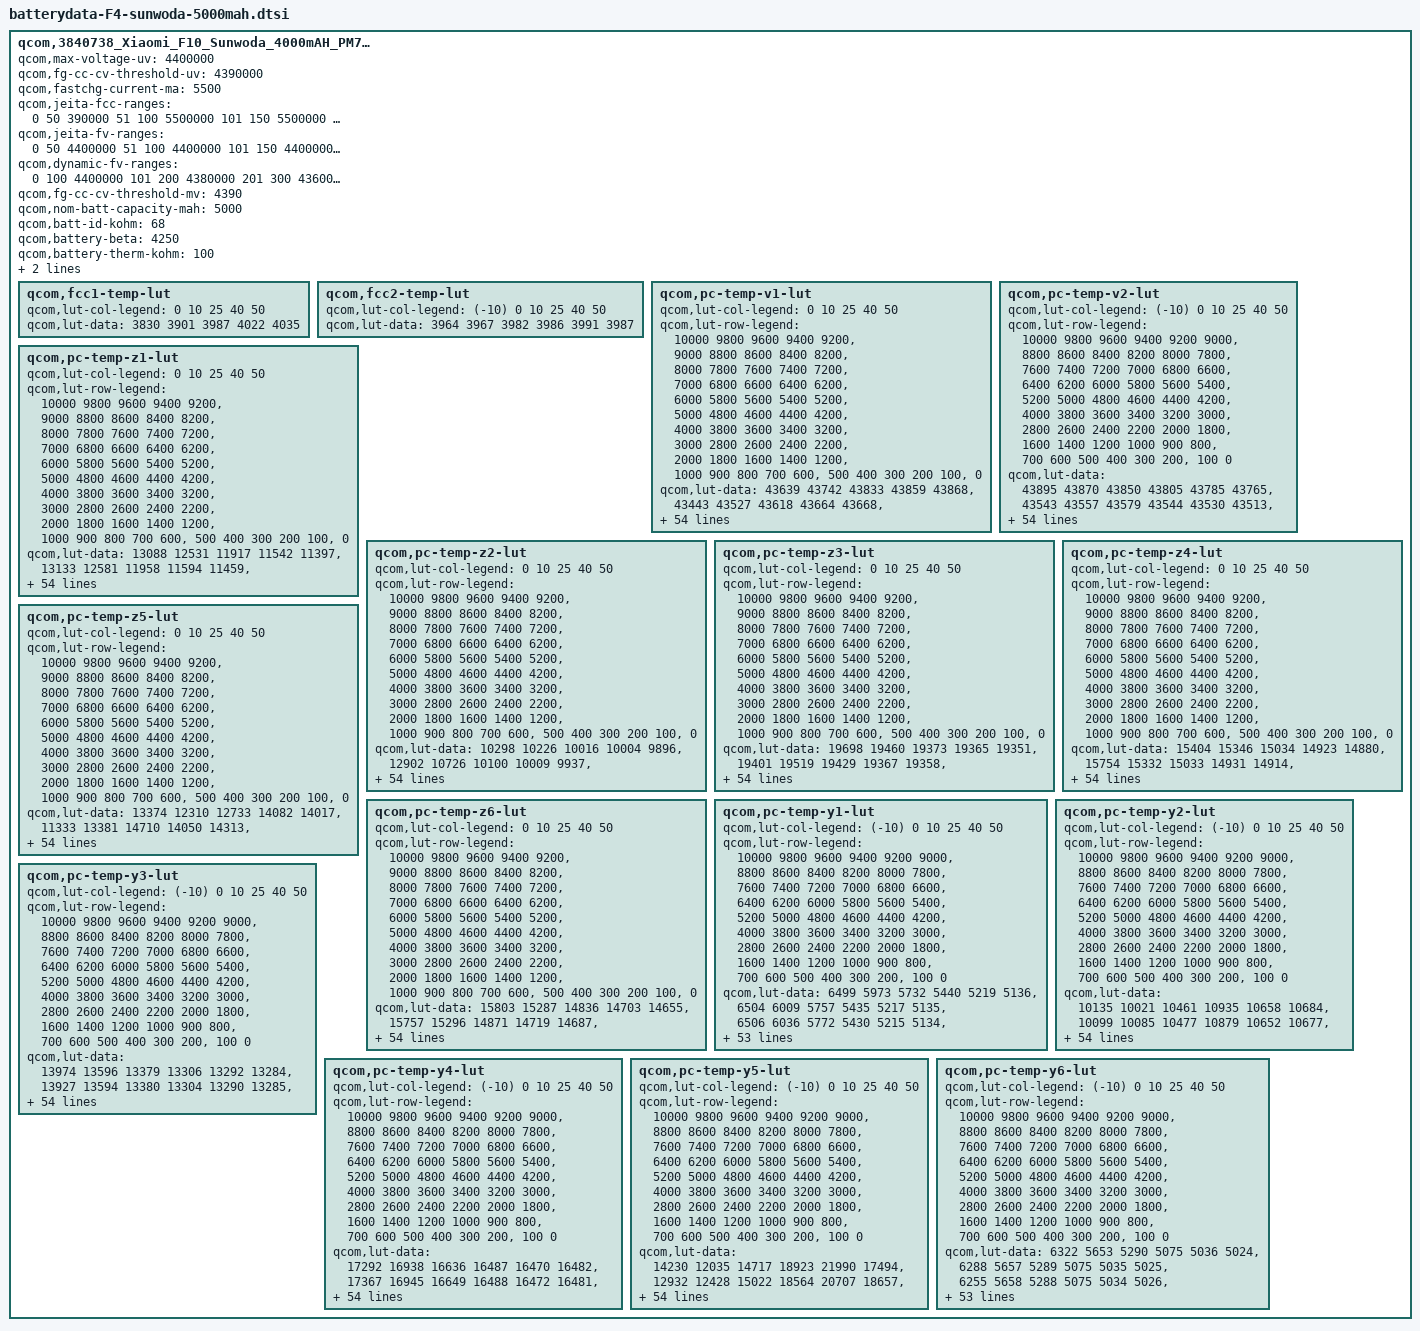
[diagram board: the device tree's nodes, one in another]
qcom,3840738_Xiaomi_F10_Sunwoda_4000mAH_PM7150_FG {
	/* 3840738_Xiaomi_F10_Sunwoda_4000mAH_PM7150_FG_averaged_MasterSlave_Feb1th2019 */
	qcom,max-voltage-uv = <4400000>;
	qcom,fg-cc-cv-threshold-uv = <4390000>;
	qcom,fastchg-current-ma = <5500>;
	qcom,jeita-fcc-ranges = <0  50  390000
				51  100  5500000
				101 150  5500000
				151 450  5500000
				451 580  1950000>;
	qcom,jeita-fv-ranges = <0   50  4400000
				51  100  4400000
				101 150  4400000
				151 450  4400000
				451 580  4100000>;
	qcom,dynamic-fv-ranges = <0    100  4400000
				  101  200  4380000
				  201  300  4360000
				  301  400  4340000
				  401  500  4340000>;
	qcom,fg-cc-cv-threshold-mv = <4390>;
	qcom,nom-batt-capacity-mah = <5000>;
	qcom,batt-id-kohm = <68>;
	qcom,battery-beta = <4250>;
	qcom,battery-therm-kohm = <100>;
	qcom,battery-type = "f10_swd";
	qcom,qg-batt-profile-ver = <100>;

	qcom,fcc1-temp-lut {
		qcom,lut-col-legend = <0 10 25 40 50>;
		qcom,lut-data = <3830 3901 3987 4022 4035>;
	};

	qcom,fcc2-temp-lut {
		qcom,lut-col-legend = <(-10) 0 10 25 40 50>;
		qcom,lut-data = <3964 3967 3982 3986 3991 3987>;
	};

	qcom,pc-temp-v1-lut {
		qcom,lut-col-legend = <0 10 25 40 50>;
		qcom,lut-row-legend = <10000 9800 9600 9400 9200>,
			<9000 8800 8600 8400 8200>,
			<8000 7800 7600 7400 7200>,
			<7000 6800 6600 6400 6200>,
			<6000 5800 5600 5400 5200>,
			<5000 4800 4600 4400 4200>,
			<4000 3800 3600 3400 3200>,
			<3000 2800 2600 2400 2200>,
			<2000 1800 1600 1400 1200>,
			<1000 900 800 700 600>,
			<500 400 300 200 100>,
			<0>;
		qcom,lut-data = <43639 43742 43833 43859 43868>,
			<43443 43527 43618 43664 43668>,
			<43186 43299 43398 43444 43455>,
			<42923 43062 43172 43220 43236>,
			<42685 42830 42941 42993 43012>,
			<42457 42600 42709 42763 42783>,
			<42233 42371 42477 42533 42555>,
			<42015 42143 42245 42302 42326>,
			<41802 41918 42018 42073 42098>,
			<41595 41698 41793 41845 41870>,
			<41392 41484 41573 41620 41644>,
			<41197 41277 41357 41401 41422>,
			<41016 41082 41146 41187 41203>,
			<40835 40904 40945 40981 40992>,
			<40623 40719 40751 40779 40787>,
			<40370 40496 40558 40582 40589>,
			<40138 40254 40355 40383 40397>,
			<39970 40060 40158 40188 40212>,
			<39828 39918 39987 40011 40036>,
			<39689 39782 39842 39864 39880>,
			<39558 39612 39676 39708 39716>,
			<39420 39418 39436 39487 39499>,
			<39238 39224 39181 39224 39236>,
			<39008 39012 39000 39028 39035>,
			<38822 38825 38862 38891 38901>,
			<38704 38714 38746 38773 38786>,
			<38612 38641 38649 38663 38670>,
			<38539 38574 38563 38562 38559>,
			<38480 38505 38479 38468 38461>,
			<38428 38440 38397 38377 38373>,
			<38379 38378 38324 38296 38293>,
			<38333 38317 38258 38227 38221>,
			<38292 38263 38199 38165 38156>,
			<38254 38216 38145 38106 38091>,
			<38219 38175 38098 38051 38027>,
			<38185 38137 38051 37997 37964>,
			<38153 38105 38008 37943 37902>,
			<38113 38067 37963 37888 37839>,
			<38050 38003 37898 37816 37759>,
			<37967 37908 37806 37720 37656>,
			<37868 37801 37700 37609 37541>,
			<37741 37675 37581 37488 37419>,
			<37599 37533 37444 37353 37284>,
			<37438 37368 37281 37191 37116>,
			<37303 37232 37147 37068 36997>,
			<37223 37152 37067 36988 36933>,
			<37200 37127 37041 36965 36910>,
			<37186 37109 37023 36946 36889>,
			<37168 37088 37008 36923 36865>,
			<37110 37033 36939 36837 36761>,
			<36847 36752 36643 36518 36422>,
			<36378 36289 36184 36057 35960>,
			<35789 35697 35582 35456 35358>,
			<34977 34871 34757 34631 34529>,
			<33685 33560 33449 33321 33215>,
			<30000 30000 30000 30000 30000>;
	};

	qcom,pc-temp-v2-lut {
		qcom,lut-col-legend = <(-10) 0 10 25 40 50>;
		qcom,lut-row-legend = <10000 9800 9600 9400 9200 9000>,
			<8800 8600 8400 8200 8000 7800>,
			<7600 7400 7200 7000 6800 6600>,
			<6400 6200 6000 5800 5600 5400>,
			<5200 5000 4800 4600 4400 4200>,
			<4000 3800 3600 3400 3200 3000>,
			<2800 2600 2400 2200 2000 1800>,
			<1600 1400 1200 1000 900 800>,
			<700 600 500 400 300 200>,
			<100 0>;
		qcom,lut-data = <43895 43870 43850 43805 43785 43765>,
			<43543 43557 43579 43544 43530 43513>,
			<43218 43262 43316 43289 43281 43268>,
			<42918 42986 43063 43044 43039 43031>,
			<42640 42730 42820 42808 42804 42801>,
			<42390 42481 42581 42574 42571 42572>,
			<42180 42234 42344 42341 42339 42340>,
			<41987 41993 42110 42109 42108 42107>,
			<41758 41758 41881 41881 41880 41878>,
			<41468 41525 41654 41655 41655 41650>,
			<41238 41309 41434 41432 41433 41426>,
			<41139 41125 41222 41214 41215 41208>,
			<41067 40956 41017 41000 41000 40993>,
			<40909 40764 40815 40796 40795 40787>,
			<40503 40547 40615 40600 40596 40585>,
			<40074 40315 40417 40405 40402 40390>,
			<39779 40055 40218 40201 40205 40200>,
			<39529 39782 40018 39999 40013 40018>,
			<39340 39555 39806 39825 39840 39846>,
			<39206 39367 39578 39682 39689 39691>,
			<39072 39193 39356 39524 39523 39521>,
			<38874 39022 39151 39293 39296 39296>,
			<38641 38858 38959 39031 39048 39049>,
			<38480 38700 38794 38835 38855 38858>,
			<38375 38545 38650 38683 38700 38707>,
			<38293 38402 38522 38554 38568 38576>,
			<38224 38274 38410 38440 38451 38456>,
			<38165 38159 38308 38338 38348 38349>,
			<38108 38081 38211 38245 38255 38254>,
			<38051 38029 38112 38159 38171 38169>,
			<37997 37987 38027 38081 38094 38092>,
			<37947 37942 37960 38009 38025 38022>,
			<37900 37899 37906 37942 37960 37956>,
			<37852 37858 37858 37879 37892 37885>,
			<37802 37820 37819 37823 37820 37808>,
			<37750 37781 37780 37766 37742 37721>,
			<37694 37738 37740 37703 37651 37619>,
			<37635 37693 37698 37636 37553 37505>,
			<37565 37636 37643 37562 37462 37406>,
			<37481 37558 37567 37480 37380 37325>,
			<37387 37463 37475 37386 37291 37240>,
			<37288 37354 37358 37275 37183 37130>,
			<37184 37228 37218 37150 37066 37008>,
			<37096 37087 37069 37019 36944 36886>,
			<37022 36958 36952 36920 36853 36801>,
			<36952 36884 36889 36871 36812 36760>,
			<36907 36853 36859 36855 36800 36747>,
			<36856 36823 36832 36838 36781 36727>,
			<36779 36776 36787 36801 36742 36684>,
			<36655 36675 36679 36690 36594 36503>,
			<36393 36432 36380 36356 36212 36108>,
			<35945 35966 35872 35838 35682 35573>,
			<35300 35324 35202 35174 34988 34869>,
			<34375 34430 34278 34271 34045 33932>,
			<32935 33097 32975 32791 32630 32448>,
			<27703 28392 27520 27513 27500 27362>;
	};

	qcom,pc-temp-z1-lut {
		qcom,lut-col-legend = <0 10 25 40 50>;
		qcom,lut-row-legend = <10000 9800 9600 9400 9200>,
			<9000 8800 8600 8400 8200>,
			<8000 7800 7600 7400 7200>,
			<7000 6800 6600 6400 6200>,
			<6000 5800 5600 5400 5200>,
			<5000 4800 4600 4400 4200>,
			<4000 3800 3600 3400 3200>,
			<3000 2800 2600 2400 2200>,
			<2000 1800 1600 1400 1200>,
			<1000 900 800 700 600>,
			<500 400 300 200 100>,
			<0>;
		qcom,lut-data = <13088 12531 11917 11542 11397>,
			<13133 12581 11958 11594 11459>,
			<13170 12587 11982 11610 11479>,
			<13190 12580 11982 11613 11487>,
			<13188 12572 11971 11612 11486>,
			<13182 12560 11959 11610 11485>,
			<13172 12548 11947 11606 11484>,
			<13140 12543 11936 11600 11483>,
			<13107 12535 11927 11598 11482>,
			<13097 12525 11920 11597 11480>,
			<13092 12510 11916 11597 11478>,
			<13088 12491 11914 11595 11477>,
			<13081 12475 11913 11594 11476>,
			<13070 12459 11911 11592 11476>,
			<13052 12449 11910 11591 11476>,
			<13009 12446 11908 11590 11475>,
			<12979 12446 11905 11588 11475>,
			<12977 12446 11901 11587 11477>,
			<12979 12450 11901 11587 11479>,
			<12980 12456 11903 11588 11479>,
			<12984 12457 11906 11590 11480>,
			<12991 12459 11909 11590 11483>,
			<13003 12459 11914 11591 11486>,
			<13024 12461 11917 11592 11487>,
			<13034 12463 11919 11594 11485>,
			<13026 12467 11922 11597 11484>,
			<13013 12471 11928 11600 11486>,
			<13011 12473 11935 11604 11491>,
			<13021 12477 11940 11608 11495>,
			<13033 12481 11945 11615 11498>,
			<13046 12482 11949 11620 11501>,
			<13064 12482 11956 11624 11505>,
			<13071 12482 11963 11627 11510>,
			<13059 12490 11968 11631 11515>,
			<13046 12504 11974 11637 11520>,
			<13045 12512 11979 11643 11526>,
			<13049 12516 11984 11648 11531>,
			<13054 12518 11989 11653 11536>,
			<13059 12522 11996 11658 11540>,
			<13065 12528 12006 11665 11543>,
			<13073 12532 12016 11671 11546>,
			<13092 12534 12026 11675 11549>,
			<13106 12539 12033 11678 11553>,
			<13126 12550 12035 11684 11557>,
			<13107 12573 12044 11692 11562>,
			<13101 12566 12050 11696 11564>,
			<13094 12583 12059 11696 11561>,
			<13100 12577 12054 11694 11563>,
			<13121 12564 12050 11698 11566>,
			<13128 12572 12057 11705 11572>,
			<13139 12610 12070 11713 11580>,
			<13125 12583 12082 11719 11586>,
			<13164 12615 12092 11733 11597>,
			<13201 12636 12114 11749 11611>,
			<13201 12636 12114 11749 11611>,
			<13201 12636 12114 11749 11611>;
	};

	qcom,pc-temp-z2-lut {
		qcom,lut-col-legend = <0 10 25 40 50>;
		qcom,lut-row-legend = <10000 9800 9600 9400 9200>,
			<9000 8800 8600 8400 8200>,
			<8000 7800 7600 7400 7200>,
			<7000 6800 6600 6400 6200>,
			<6000 5800 5600 5400 5200>,
			<5000 4800 4600 4400 4200>,
			<4000 3800 3600 3400 3200>,
			<3000 2800 2600 2400 2200>,
			<2000 1800 1600 1400 1200>,
			<1000 900 800 700 600>,
			<500 400 300 200 100>,
			<0>;
		qcom,lut-data = <10298 10226 10016 10004 9896>,
			<12902 10726 10100 10009 9937>,
			<11279 10665 10152 10040 9996>,
			<10100 10464 10155 10062 10029>,
			<10052 10405 10141 10073 10047>,
			<10039 10484 10125 10079 10059>,
			<10025 10558 10106 10067 10046>,
			<10006 10478 10087 10044 10006>,
			<9993 10222 10076 10030 9980>,
			<9989 10063 10067 10023 9970>,
			<9988 10062 10063 10016 9962>,
			<9989 10063 10066 9985 9952>,
			<10022 10067 10073 9920 9932>,
			<10066 10090 10210 9896 9920>,
			<10068 10110 10727 9917 9919>,
			<10025 10112 11028 9937 9919>,
			<9992 10114 11030 9932 9920>,
			<10006 10116 10999 9916 9919>,
			<10040 10128 10848 9911 9922>,
			<10063 10144 10370 9917 9932>,
			<10078 10161 10099 9928 9954>,
			<10088 10180 10160 10020 10044>,
			<10094 10187 10244 10213 10245>,
			<10098 10180 10243 10263 10319>,
			<10100 10173 10178 10130 10188>,
			<10100 10172 10140 10012 10052>,
			<10100 10174 10154 10082 10109>,
			<10100 10177 10177 10237 10281>,
			<10106 10178 10190 10277 10334>,
			<10113 10179 10201 10209 10200>,
			<10118 10182 10205 10128 10039>,
			<10124 10191 10188 10076 9948>,
			<10131 10200 10162 10032 9877>,
			<10141 10207 10162 9995 9863>,
			<10151 10212 10183 9959 9888>,
			<10162 10218 10200 9939 9920>,
			<10174 10223 10207 9962 9952>,
			<10187 10230 10215 10013 9989>,
			<10200 10244 10234 10045 10013>,
			<10213 10266 10277 10065 10029>,
			<10225 10282 10310 10081 10041>,
			<10234 10291 10322 10091 10051>,
			<10250 10302 10326 10104 10060>,
			<10287 10324 10326 10164 10083>,
			<10515 10457 10354 10159 10072>,
			<10566 10498 10320 10102 10030>,
			<10558 10502 10340 10136 10051>,
			<10544 10490 10313 10124 10032>,
			<10527 10509 10310 10148 10087>,
			<10615 10575 10420 10185 10076>,
			<10633 10617 10340 10061 9966>,
			<10559 10547 10299 9957 9864>,
			<10341 10585 10269 9927 9830>,
			<10223 10502 10191 9907 9781>,
			<10223 10502 10191 9907 9781>,
			<10223 10502 10191 9907 9781>;
	};

	qcom,pc-temp-z3-lut {
		qcom,lut-col-legend = <0 10 25 40 50>;
		qcom,lut-row-legend = <10000 9800 9600 9400 9200>,
			<9000 8800 8600 8400 8200>,
			<8000 7800 7600 7400 7200>,
			<7000 6800 6600 6400 6200>,
			<6000 5800 5600 5400 5200>,
			<5000 4800 4600 4400 4200>,
			<4000 3800 3600 3400 3200>,
			<3000 2800 2600 2400 2200>,
			<2000 1800 1600 1400 1200>,
			<1000 900 800 700 600>,
			<500 400 300 200 100>,
			<0>;
		qcom,lut-data = <19698 19460 19373 19365 19351>,
			<19401 19519 19429 19367 19358>,
			<19605 19548 19467 19401 19388>,
			<19765 19588 19481 19423 19410>,
			<19786 19614 19489 19433 19420>,
			<19797 19639 19493 19439 19427>,
			<19799 19666 19494 19442 19429>,
			<19792 19665 19496 19443 19431>,
			<19782 19636 19495 19443 19432>,
			<19773 19612 19491 19441 19428>,
			<19762 19607 19486 19436 19423>,
			<19757 19603 19477 19429 19418>,
			<19765 19595 19469 19419 19415>,
			<19776 19574 19473 19414 19411>,
			<19777 19558 19494 19412 19408>,
			<19767 19564 19505 19411 19404>,
			<19754 19577 19502 19409 19400>,
			<19734 19580 19496 19408 19396>,
			<19710 19561 19483 19406 19391>,
			<19699 19543 19453 19396 19383>,
			<19696 19550 19437 19387 19377>,
			<19694 19575 19447 19393 19381>,
			<19705 19587 19460 19406 19392>,
			<19741 19584 19459 19409 19395>,
			<19761 19580 19442 19389 19380>,
			<19756 19575 19433 19371 19364>,
			<19745 19568 19433 19383 19383>,
			<19734 19564 19435 19410 19432>,
			<19724 19563 19441 19427 19449>,
			<19713 19564 19458 19438 19442>,
			<19704 19565 19469 19444 19432>,
			<19695 19570 19470 19439 19423>,
			<19687 19573 19469 19429 19413>,
			<19680 19572 19467 19419 19403>,
			<19675 19568 19460 19409 19394>,
			<19671 19563 19453 19401 19386>,
			<19669 19555 19447 19394 19381>,
			<19666 19548 19441 19389 19377>,
			<19660 19544 19438 19386 19375>,
			<19653 19541 19437 19385 19374>,
			<19646 19537 19435 19384 19373>,
			<19640 19531 19430 19386 19376>,
			<19632 19525 19425 19390 19383>,
			<19613 19517 19425 19395 19392>,
			<19546 19483 19416 19388 19391>,
			<19510 19464 19391 19373 19371>,
			<19483 19461 19391 19355 19355>,
			<19425 19456 19392 19351 19352>,
			<19351 19457 19373 19352 19337>,
			<19348 19425 19358 19349 19348>,
			<19398 19427 19391 19386 19379>,
			<19401 19440 19402 19391 19383>,
			<19343 19362 19412 19393 19383>,
			<19338 19360 19402 19381 19382>,
			<19338 19360 19402 19381 19382>,
			<19338 19360 19402 19381 19382>;
	};

	qcom,pc-temp-z4-lut {
		qcom,lut-col-legend = <0 10 25 40 50>;
		qcom,lut-row-legend = <10000 9800 9600 9400 9200>,
			<9000 8800 8600 8400 8200>,
			<8000 7800 7600 7400 7200>,
			<7000 6800 6600 6400 6200>,
			<6000 5800 5600 5400 5200>,
			<5000 4800 4600 4400 4200>,
			<4000 3800 3600 3400 3200>,
			<3000 2800 2600 2400 2200>,
			<2000 1800 1600 1400 1200>,
			<1000 900 800 700 600>,
			<500 400 300 200 100>,
			<0>;
		qcom,lut-data = <15404 15346 15034 14923 14880>,
			<15754 15332 15033 14931 14914>,
			<15611 15285 15027 14928 14907>,
			<15449 15174 15008 14921 14896>,
			<15326 15062 14951 14893 14875>,
			<15215 14951 14899 14856 14846>,
			<15131 14861 14863 14829 14821>,
			<15068 14845 14831 14805 14797>,
			<15019 14844 14803 14784 14779>,
			<14983 14842 14778 14765 14765>,
			<14956 14827 14760 14751 14754>,
			<14924 14801 14753 14748 14748>,
			<14862 14784 14746 14746 14744>,
			<14803 14772 14724 14742 14740>,
			<14795 14766 14677 14732 14734>,
			<14812 14765 14651 14721 14728>,
			<14825 14766 14650 14716 14723>,
			<14822 14764 14650 14714 14719>,
			<14812 14754 14654 14709 14715>,
			<14802 14744 14669 14699 14707>,
			<14787 14745 14691 14692 14700>,
			<14775 14752 14743 14719 14723>,
			<14785 14764 14807 14789 14793>,
			<14824 14820 14841 14831 14832>,
			<14852 14880 14864 14854 14846>,
			<14858 14884 14873 14866 14854>,
			<14863 14867 14862 14846 14827>,
			<14862 14848 14839 14797 14758>,
			<14851 14829 14814 14763 14727>,
			<14836 14809 14782 14739 14722>,
			<14825 14791 14756 14723 14718>,
			<14813 14773 14740 14714 14712>,
			<14802 14760 14728 14709 14706>,
			<14792 14753 14722 14706 14703>,
			<14782 14748 14718 14706 14700>,
			<14773 14745 14716 14705 14698>,
			<14763 14742 14715 14703 14697>,
			<14758 14741 14714 14701 14696>,
			<14760 14744 14716 14703 14698>,
			<14762 14750 14724 14715 14714>,
			<14763 14753 14730 14724 14727>,
			<14761 14751 14728 14720 14720>,
			<14759 14748 14725 14713 14711>,
			<14754 14742 14723 14712 14712>,
			<14729 14718 14706 14701 14698>,
			<14729 14703 14702 14686 14678>,
			<14752 14695 14688 14691 14678>,
			<14810 14691 14672 14675 14660>,
			<14884 14682 14675 14650 14649>,
			<14882 14714 14693 14652 14636>,
			<14833 14726 14689 14665 14671>,
			<14842 14722 14686 14673 14681>,
			<14917 14813 14678 14679 14689>,
			<14931 14816 14695 14695 14694>,
			<14931 14816 14695 14695 14694>,
			<14931 14816 14695 14695 14694>;
	};

	qcom,pc-temp-z5-lut {
		qcom,lut-col-legend = <0 10 25 40 50>;
		qcom,lut-row-legend = <10000 9800 9600 9400 9200>,
			<9000 8800 8600 8400 8200>,
			<8000 7800 7600 7400 7200>,
			<7000 6800 6600 6400 6200>,
			<6000 5800 5600 5400 5200>,
			<5000 4800 4600 4400 4200>,
			<4000 3800 3600 3400 3200>,
			<3000 2800 2600 2400 2200>,
			<2000 1800 1600 1400 1200>,
			<1000 900 800 700 600>,
			<500 400 300 200 100>,
			<0>;
		qcom,lut-data = <13374 12310 12733 14082 14017>,
			<11333 13381 14710 14050 14313>,
			<12978 13902 16154 15980 16270>,
			<14542 14809 16863 17355 17924>,
			<15211 15603 17270 18010 18784>,
			<15699 17130 17707 18532 19457>,
			<16017 18918 18278 19059 20085>,
			<16272 19204 18919 19558 20657>,
			<16426 18912 19694 20170 21213>,
			<16480 18707 20626 21174 21819>,
			<16655 19207 21121 21927 22375>,
			<16956 20098 21242 21650 22736>,
			<18130 20296 21353 20791 23037>,
			<19772 19946 23715 20515 23307>,
			<20884 19652 32353 21343 23908>,
			<21850 20965 37442 22531 24636>,
			<22378 23792 37192 23622 24986>,
			<21858 24625 36041 24728 25320>,
			<20724 22998 33868 25184 25676>,
			<20344 21404 28619 25287 26153>,
			<21189 25507 25709 25399 26805>,
			<22957 37694 30185 26923 27875>,
			<28882 43197 36308 30044 29382>,
			<43056 39484 35238 30341 29549>,
			<50759 33702 26329 23046 23057>,
			<46668 29529 20285 16641 16508>,
			<39370 25555 19040 16974 18462>,
			<34684 23726 18352 18504 24585>,
			<31416 23645 18711 20549 27149>,
			<29160 23651 21085 24332 27506>,
			<27904 24197 23745 27100 27663>,
			<27011 27079 26209 27399 27468>,
			<26760 29983 28546 27535 26999>,
			<26842 31709 30055 27540 26838>,
			<27014 33043 31253 27279 27069>,
			<27586 33235 31752 27077 27332>,
			<29114 32129 31406 27052 27563>,
			<30077 30884 30660 26970 27875>,
			<30130 30332 29766 26692 27731>,
			<30036 29924 28471 25444 25702>,
			<29699 29279 26911 24188 23987>,
			<28774 27497 24470 23451 24050>,
			<28396 26347 22846 23048 24663>,
			<27628 26036 22996 24469 28658>,
			<27491 26498 23145 23680 29794>,
			<23369 25476 19888 20007 21882>,
			<21377 25294 20518 16788 17652>,
			<17409 24403 22055 17334 18820>,
			<12662 25668 18737 20523 18880>,
			<12859 18518 16192 19097 24482>,
			<14848 18523 18635 23260 23678>,
			<15035 18900 19370 21258 20434>,
			<12343 13215 20482 19427 17970>,
			<12074 13019 17769 15808 15755>,
			<12074 13019 17769 15808 15755>,
			<12074 13019 17769 15808 15755>;
	};

	qcom,pc-temp-z6-lut {
		qcom,lut-col-legend = <0 10 25 40 50>;
		qcom,lut-row-legend = <10000 9800 9600 9400 9200>,
			<9000 8800 8600 8400 8200>,
			<8000 7800 7600 7400 7200>,
			<7000 6800 6600 6400 6200>,
			<6000 5800 5600 5400 5200>,
			<5000 4800 4600 4400 4200>,
			<4000 3800 3600 3400 3200>,
			<3000 2800 2600 2400 2200>,
			<2000 1800 1600 1400 1200>,
			<1000 900 800 700 600>,
			<500 400 300 200 100>,
			<0>;
		qcom,lut-data = <15803 15287 14836 14703 14655>,
			<15757 15296 14871 14719 14687>,
			<15737 15279 14888 14741 14704>,
			<15713 15229 14884 14748 14711>,
			<15658 15178 14862 14741 14707>,
			<15578 15138 14839 14729 14699>,
			<15513 15099 14823 14719 14691>,
			<15461 15069 14807 14709 14682>,
			<15417 15044 14792 14700 14673>,
			<15383 15022 14777 14690 14665>,
			<15355 15004 14765 14682 14657>,
			<15327 14988 14757 14675 14652>,
			<15291 14969 14749 14669 14648>,
			<15258 14946 14742 14663 14643>,
			<15239 14931 14735 14657 14639>,
			<15229 14933 14729 14652 14634>,
			<15219 14936 14725 14648 14629>,
			<15205 14937 14722 14646 14625>,
			<15191 14923 14717 14642 14620>,
			<15182 14910 14709 14632 14612>,
			<15177 14913 14705 14625 14606>,
			<15174 14928 14731 14641 14619>,
			<15184 14946 14770 14681 14657>,
			<15223 14971 14780 14694 14672>,
			<15246 14993 14784 14693 14670>,
			<15246 14994 14785 14693 14667>,
			<15244 14985 14781 14691 14665>,
			<15241 14976 14773 14686 14662>,
			<15233 14969 14768 14682 14659>,
			<15223 14962 14764 14678 14654>,
			<15215 14958 14760 14674 14648>,
			<15207 14954 14755 14668 14642>,
			<15200 14952 14751 14662 14635>,
			<15193 14949 14747 14656 14628>,
			<15188 14946 14742 14651 14623>,
			<15186 14944 14739 14646 14618>,
			<15186 14941 14736 14642 14615>,
			<15185 14940 14734 14638 14612>,
			<15187 14942 14735 14638 14612>,
			<15191 14947 14740 14643 14617>,
			<15194 14949 14743 14647 14622>,
			<15197 14950 14741 14647 14622>,
			<15198 14950 14740 14647 14622>,
			<15197 14950 14740 14650 14628>,
			<15169 14934 14731 14643 14623>,
			<15155 14919 14718 14629 14603>,
			<15151 14914 14712 14622 14595>,
			<15145 14911 14706 14612 14586>,
			<15141 14909 14698 14602 14572>,
			<15144 14909 14699 14602 14574>,
			<15156 14923 14718 14630 14608>,
			<15169 14932 14726 14639 14617>,
			<15181 14939 14731 14645 14624>,
			<15204 14951 14738 14650 14629>,
			<15204 14951 14738 14650 14629>,
			<15204 14951 14738 14650 14629>;
	};

	qcom,pc-temp-y1-lut {
		qcom,lut-col-legend = <(-10) 0 10 25 40 50>;
		qcom,lut-row-legend = <10000 9800 9600 9400 9200 9000>,
			<8800 8600 8400 8200 8000 7800>,
			<7600 7400 7200 7000 6800 6600>,
			<6400 6200 6000 5800 5600 5400>,
			<5200 5000 4800 4600 4400 4200>,
			<4000 3800 3600 3400 3200 3000>,
			<2800 2600 2400 2200 2000 1800>,
			<1600 1400 1200 1000 900 800>,
			<700 600 500 400 300 200>,
			<100 0>;
		qcom,lut-data = <6499 5973 5732 5440 5219 5136>,
			<6504 6009 5757 5435 5217 5135>,
			<6506 6036 5772 5430 5215 5134>,
			<6506 6055 5780 5424 5212 5133>,
			<6504 6066 5783 5420 5210 5132>,
			<6501 6070 5783 5416 5208 5131>,
			<6491 6061 5775 5413 5206 5131>,
			<6479 6045 5760 5410 5204 5130>,
			<6476 6040 5756 5409 5202 5129>,
			<6476 6041 5758 5408 5200 5127>,
			<6477 6043 5759 5408 5198 5126>,
			<6493 6049 5754 5405 5198 5126>,
			<6524 6058 5747 5401 5197 5126>,
			<6534 6062 5745 5400 5197 5126>,
			<6533 6061 5750 5401 5195 5126>,
			<6530 6059 5754 5402 5195 5125>,
			<6518 6062 5754 5403 5195 5125>,
			<6500 6068 5755 5403 5196 5126>,
			<6494 6072 5758 5403 5196 5126>,
			<6504 6075 5768 5403 5196 5126>,
			<6514 6077 5776 5404 5196 5126>,
			<6516 6076 5773 5406 5196 5126>,
			<6521 6075 5767 5411 5198 5127>,
			<6517 6074 5765 5415 5201 5127>,
			<6494 6075 5772 5420 5203 5129>,
			<6474 6076 5777 5424 5206 5131>,
			<6484 6072 5775 5427 5209 5133>,
			<6510 6064 5772 5431 5213 5136>,
			<6519 6060 5773 5435 5215 5138>,
			<6508 6057 5776 5442 5217 5142>,
			<6492 6054 5780 5449 5219 5146>,
			<6477 6057 5786 5456 5223 5149>,
			<6460 6068 5792 5462 5229 5151>,
			<6451 6074 5794 5466 5234 5153>,
			<6449 6071 5794 5471 5237 5156>,
			<6448 6066 5793 5475 5240 5158>,
			<6453 6063 5794 5480 5243 5160>,
			<6463 6061 5796 5485 5245 5163>,
			<6466 6058 5797 5488 5247 5164>,
			<6458 6051 5802 5488 5248 5165>,
			<6453 6046 5808 5490 5250 5166>,
			<6460 6050 5815 5492 5252 5167>,
			<6470 6059 5823 5496 5254 5169>,
			<6459 6055 5817 5506 5261 5173>,
			<6439 6051 5811 5519 5268 5178>,
			<6477 6057 5822 5527 5268 5179>,
			<6480 6077 5821 5527 5267 5178>,
			<6474 6097 5818 5522 5267 5177>,
			<6519 6070 5819 5524 5266 5181>,
			<6500 6070 5825 5520 5268 5181>,
			<6499 6076 5831 5526 5271 5184>,
			<6487 6077 5820 5548 5278 5189>,
			<6539 6105 5834 5562 5287 5197>,
			<6573 6124 5867 5569 5299 5208>,
			<6573 6124 5867 5569 5299 5208>,
			<6573 6124 5867 5569 5299 5208>;
	};

	qcom,pc-temp-y2-lut {
		qcom,lut-col-legend = <(-10) 0 10 25 40 50>;
		qcom,lut-row-legend = <10000 9800 9600 9400 9200 9000>,
			<8800 8600 8400 8200 8000 7800>,
			<7600 7400 7200 7000 6800 6600>,
			<6400 6200 6000 5800 5600 5400>,
			<5200 5000 4800 4600 4400 4200>,
			<4000 3800 3600 3400 3200 3000>,
			<2800 2600 2400 2200 2000 1800>,
			<1600 1400 1200 1000 900 800>,
			<700 600 500 400 300 200>,
			<100 0>;
		qcom,lut-data = <10135 10021 10461 10935 10658 10684>,
			<10099 10085 10477 10879 10652 10677>,
			<10091 10139 10488 10807 10638 10666>,
			<10105 10179 10494 10733 10620 10653>,
			<10136 10205 10497 10675 10606 10639>,
			<10178 10214 10498 10649 10599 10624>,
			<10237 10200 10494 10650 10590 10608>,
			<10313 10176 10488 10658 10575 10590>,
			<10386 10185 10488 10660 10566 10570>,
			<10465 10288 10498 10658 10559 10544>,
			<10522 10383 10510 10658 10552 10524>,
			<10545 10413 10518 10663 10532 10512>,
			<10564 10436 10527 10670 10508 10502>,
			<10615 10468 10557 10681 10509 10503>,
			<10796 10531 10661 10698 10548 10527>,
			<10932 10607 10751 10722 10598 10545>,
			<10591 10681 10780 10765 10649 10539>,
			<9893 10762 10799 10827 10709 10529>,
			<9684 10862 10822 10893 10772 10557>,
			<9683 11014 10848 10979 10851 10722>,
			<9682 11114 10873 11028 10893 10840>,
			<9679 11044 10895 10997 10846 10807>,
			<9674 10880 10917 10941 10767 10748>,
			<9671 10816 10949 10931 10747 10729>,
			<9670 10808 10997 10957 10757 10724>,
			<9669 10802 11044 10986 10769 10722>,
			<9668 10699 11084 11005 10790 10732>,
			<9667 10425 11119 11028 10822 10754>,
			<9667 10253 11124 11058 10847 10778>,
			<9666 9957 11102 11119 10874 10806>,
			<9665 9709 11084 11174 10902 10831>,
			<9664 9694 11087 11204 10943 10846>,
			<9664 9691 11092 11225 10989 10859>,
			<9663 9687 11093 11233 11003 10873>,
			<9663 9683 11081 11229 11014 10907>,
			<9663 9679 11062 11217 11015 10933>,
			<9663 9676 11043 11192 10978 10905>,
			<9662 9672 11019 11155 10925 10848>,
			<9662 9670 10994 11130 10909 10830>,
			<9661 9668 10965 11109 10905 10835>,
			<9661 9666 10928 11091 10901 10839>,
			<9661 9664 10866 11077 10893 10815>,
			<9660 9663 10769 11056 10876 10756>,
			<9660 9661 10677 11015 10822 10682>,
			<9660 9660 10540 10945 10726 10588>,
			<9659 9659 10346 10917 10677 10555>,
			<9659 9659 10162 10918 10685 10547>,
			<9659 9659 10050 10922 10705 10529>,
			<9658 9658 9990 10928 10756 10568>,
			<9658 9657 10126 10946 10734 10573>,
			<9657 9657 9853 10893 10661 10540>,
			<9656 9656 9719 10818 10615 10474>,
			<9655 9656 9685 10765 10541 10393>,
			<9653 9655 9672 10715 10454 10282>,
			<9653 9655 9672 10715 10454 10282>,
			<9653 9655 9672 10715 10454 10282>;
	};

	qcom,pc-temp-y3-lut {
		qcom,lut-col-legend = <(-10) 0 10 25 40 50>;
		qcom,lut-row-legend = <10000 9800 9600 9400 9200 9000>,
			<8800 8600 8400 8200 8000 7800>,
			<7600 7400 7200 7000 6800 6600>,
			<6400 6200 6000 5800 5600 5400>,
			<5200 5000 4800 4600 4400 4200>,
			<4000 3800 3600 3400 3200 3000>,
			<2800 2600 2400 2200 2000 1800>,
			<1600 1400 1200 1000 900 800>,
			<700 600 500 400 300 200>,
			<100 0>;
		qcom,lut-data = <13974 13596 13379 13306 13292 13284>,
			<13927 13594 13380 13304 13290 13285>,
			<13883 13591 13382 13302 13289 13286>,
			<13847 13588 13383 13302 13288 13287>,
			<13821 13584 13384 13302 13288 13288>,
			<13811 13580 13385 13303 13288 13288>,
			<13821 13572 13386 13304 13289 13289>,
			<13837 13563 13386 13305 13291 13289>,
			<13817 13564 13386 13306 13292 13289>,
			<13659 13582 13384 13307 13293 13290>,
			<13540 13596 13383 13307 13294 13291>,
			<13543 13548 13385 13308 13296 13292>,
			<13554 13459 13389 13310 13298 13293>,
			<13556 13440 13388 13312 13300 13295>,
			<13547 13469 13374 13315 13301 13296>,
			<13535 13491 13364 13317 13302 13297>,
			<13509 13481 13367 13315 13303 13298>,
			<13474 13455 13370 13312 13304 13298>,
			<13467 13431 13370 13311 13303 13298>,
			<13487 13406 13363 13313 13302 13299>,
			<13505 13384 13355 13314 13300 13299>,
			<13497 13367 13348 13311 13296 13294>,
			<13475 13354 13342 13305 13290 13287>,
			<13465 13351 13337 13301 13289 13285>,
			<13463 13355 13332 13300 13288 13286>,
			<13463 13359 13328 13298 13288 13286>,
			<13474 13355 13324 13297 13287 13285>,
			<13501 13345 13321 13296 13286 13284>,
			<13525 13337 13320 13296 13286 13284>,
			<13542 13329 13318 13296 13285 13285>,
			<13560 13322 13317 13296 13285 13286>,
			<13582 13328 13317 13295 13286 13286>,
			<13608 13347 13318 13295 13287 13286>,
			<13633 13365 13318 13295 13288 13286>,
			<13656 13380 13318 13295 13289 13287>,
			<13679 13395 13319 13295 13289 13287>,
			<13704 13413 13320 13295 13288 13287>,
			<13732 13434 13322 13295 13287 13286>,
			<13762 13457 13323 13296 13287 13286>,
			<13794 13481 13324 13296 13288 13288>,
			<13826 13509 13325 13296 13289 13290>,
			<13856 13546 13325 13296 13290 13289>,
			<13885 13594 13324 13296 13290 13288>,
			<13922 13645 13327 13295 13288 13288>,
			<13972 13705 13331 13297 13289 13289>,
			<14022 13762 13334 13302 13296 13294>,
			<13998 13748 13331 13305 13299 13296>,
			<14050 13804 13338 13311 13301 13298>,
			<14108 13859 13350 13315 13303 13299>,
			<14176 13919 13365 13316 13299 13295>,
			<14241 13968 13374 13310 13296 13295>,
			<14342 14029 13397 13312 13299 13298>,
			<14507 14142 13438 13319 13305 13304>,
			<14903 14279 13504 13333 13316 13315>,
			<14903 14279 13504 13333 13316 13315>,
			<14903 14279 13504 13333 13316 13315>;
	};

	qcom,pc-temp-y4-lut {
		qcom,lut-col-legend = <(-10) 0 10 25 40 50>;
		qcom,lut-row-legend = <10000 9800 9600 9400 9200 9000>,
			<8800 8600 8400 8200 8000 7800>,
			<7600 7400 7200 7000 6800 6600>,
			<6400 6200 6000 5800 5600 5400>,
			<5200 5000 4800 4600 4400 4200>,
			<4000 3800 3600 3400 3200 3000>,
			<2800 2600 2400 2200 2000 1800>,
			<1600 1400 1200 1000 900 800>,
			<700 600 500 400 300 200>,
			<100 0>;
		qcom,lut-data = <17292 16938 16636 16487 16470 16482>,
			<17367 16945 16649 16488 16472 16481>,
			<17400 16955 16657 16490 16473 16480>,
			<17402 16966 16663 16493 16474 16479>,
			<17380 16976 16665 16495 16475 16479>,
			<17346 16981 16666 16496 16476 16478>,
			<17258 16983 16663 16497 16476 16478>,
			<17144 16985 16658 16497 16476 16478>,
			<17151 16974 16657 16499 16477 16479>,
			<17372 16903 16659 16505 16479 16479>,
			<17549 16851 16662 16511 16482 16480>,
			<17573 16979 16666 16515 16484 16482>,
			<17586 17214 16672 16521 16487 16484>,
			<17550 17263 16691 16528 16491 16486>,
			<17250 17158 16766 16540 16498 16490>,
			<17008 17040 16818 16554 16505 16495>,
			<17016 16964 16812 16572 16512 16501>,
			<17042 16902 16795 16592 16520 16509>,
			<17045 16874 16769 16613 16537 16523>,
			<16988 16864 16716 16639 16575 16552>,
			<16910 16854 16664 16654 16599 16571>,
			<16828 16832 16626 16612 16572 16551>,
			<16743 16796 16595 16533 16520 16513>,
			<16719 16750 16579 16499 16493 16492>,
			<16726 16668 16570 16486 16477 16480>,
			<16732 16602 16565 16480 16470 16474>,
			<16728 16586 16563 16482 16471 16474>,
			<16717 16581 16562 16487 16475 16475>,
			<16713 16587 16557 16492 16480 16477>,
			<16716 16621 16539 16497 16491 16484>,
			<16721 16652 16524 16502 16502 16492>,
			<16723 16655 16524 16508 16511 16505>,
			<16724 16654 16526 16514 16518 16518>,
			<16726 16655 16530 16517 16519 16522>,
			<16730 16662 16543 16519 16518 16522>,
			<16735 16671 16558 16520 16515 16522>,
			<16740 16681 16571 16516 16503 16510>,
			<16745 16692 16584 16509 16485 16487>,
			<16747 16696 16589 16505 16481 16482>,
			<16740 16695 16590 16504 16485 16490>,
			<16731 16694 16591 16504 16488 16497>,
			<16726 16689 16590 16504 16486 16494>,
			<16723 16677 16586 16504 16481 16485>,
			<16726 16663 16578 16502 16470 16466>,
			<16739 16655 16576 16503 16468 16463>,
			<16759 16655 16582 16505 16494 16511>,
			<16750 16655 16597 16515 16525 16545>,
			<16772 16675 16623 16542 16560 16581>,
			<16800 16707 16654 16576 16588 16604>,
			<16817 16740 16673 16582 16562 16551>,
			<16811 16742 16671 16528 16493 16493>,
			<16786 16722 16665 16523 16488 16490>,
			<16787 16727 16688 16546 16496 16493>,
			<16899 16756 16740 16594 16542 16545>,
			<16899 16756 16740 16594 16542 16545>,
			<16899 16756 16740 16594 16542 16545>;
	};

	qcom,pc-temp-y5-lut {
		qcom,lut-col-legend = <(-10) 0 10 25 40 50>;
		qcom,lut-row-legend = <10000 9800 9600 9400 9200 9000>,
			<8800 8600 8400 8200 8000 7800>,
			<7600 7400 7200 7000 6800 6600>,
			<6400 6200 6000 5800 5600 5400>,
			<5200 5000 4800 4600 4400 4200>,
			<4000 3800 3600 3400 3200 3000>,
			<2800 2600 2400 2200 2000 1800>,
			<1600 1400 1200 1000 900 800>,
			<700 600 500 400 300 200>,
			<100 0>;
		qcom,lut-data = <14230 12035 14717 18923 21990 17494>,
			<12932 12428 15022 18564 20707 18657>,
			<12349 12911 15377 17987 19354 19364>,
			<12331 13387 15732 17353 18105 19729>,
			<12728 13757 16034 16823 17135 19865>,
			<13391 13923 16232 16560 16621 19885>,
			<15459 13883 16356 16444 16552 19539>,
			<18252 13802 16444 16253 16642 18825>,
			<18338 13977 16409 15975 16640 18187>,
			<14707 15134 16089 15461 16444 17516>,
			<11979 15986 15719 14988 16295 17056>,
			<13250 14923 15314 14683 16383 16929>,
			<16139 12966 14856 14446 16487 16867>,
			<18385 12945 14615 14313 16288 16676>,
			<20468 16637 14463 14205 15764 16356>,
			<21643 19583 14394 14138 15321 15972>,
			<19461 18861 16234 14042 15079 15420>,
			<15022 17291 19546 13942 14896 14863>,
			<14009 16789 20518 14354 14864 14762>,
			<16803 16749 20570 16799 14987 14861>,
			<19239 16744 20480 19216 15284 15034>,
			<18212 17028 20243 20547 16764 15930>,
			<15459 17911 19875 21518 18991 17580>,
			<13733 19365 19484 21611 19866 18863>,
			<12720 23296 18974 20945 20112 20077>,
			<12160 26434 18670 20123 20030 20735>,
			<12293 23791 18933 19274 18930 19537>,
			<12667 17008 19529 18404 17263 17283>,
			<12802 13833 19944 18157 16469 16466>,
			<12752 13032 20483 18385 15904 16228>,
			<12702 12652 20805 18569 15613 16129>,
			<12793 12712 20393 18709 16131 16219>,
			<13095 12959 19623 19044 17299 16493>,
			<13341 13226 19308 19252 18399 17046>,
			<13548 13507 18872 19713 19668 18698>,
			<13740 13808 18473 20039 20362 20052>,
			<13906 14154 18469 19987 20082 20310>,
			<14130 14550 18602 19823 19587 20454>,
			<14259 14712 18557 19519 19393 20737>,
			<14256 14537 18371 18661 19276 21348>,
			<14164 14305 18144 17854 19258 22046>,
			<13836 14307 17547 17458 20149 23138>,
			<13240 14410 16729 17045 21238 24067>,
			<13015 14139 16783 16260 18827 21403>,
			<12966 13717 16771 16036 16528 18163>,
			<13220 13972 15929 16543 16569 15610>,
			<13236 13830 14410 16911 16151 15037>,
			<13375 13993 14285 17520 15825 14672>,
			<13477 13926 14471 17640 15870 14663>,
			<14073 14149 15806 18014 15543 14707>,
			<13997 14427 14931 18212 16930 16093>,
			<13804 14128 14566 18854 17572 16420>,
			<13507 13988 14538 19667 18705 17374>,
			<13029 14263 15107 22152 23922 24346>,
			<13029 14263 15107 22152 23922 24346>,
			<13029 14263 15107 22152 23922 24346>;
	};

	qcom,pc-temp-y6-lut {
		qcom,lut-col-legend = <(-10) 0 10 25 40 50>;
		qcom,lut-row-legend = <10000 9800 9600 9400 9200 9000>,
			<8800 8600 8400 8200 8000 7800>,
			<7600 7400 7200 7000 6800 6600>,
			<6400 6200 6000 5800 5600 5400>,
			<5200 5000 4800 4600 4400 4200>,
			<4000 3800 3600 3400 3200 3000>,
			<2800 2600 2400 2200 2000 1800>,
			<1600 1400 1200 1000 900 800>,
			<700 600 500 400 300 200>,
			<100 0>;
		qcom,lut-data = <6322 5653 5290 5075 5036 5024>,
			<6288 5657 5289 5075 5035 5025>,
			<6255 5658 5288 5075 5034 5026>,
			<6224 5657 5286 5075 5034 5027>,
			<6197 5653 5283 5075 5034 5027>,
			<6175 5648 5280 5075 5034 5028>,
			<6159 5641 5275 5076 5035 5028>,
			<6145 5632 5271 5077 5036 5028>,
			<6124 5624 5267 5078 5037 5028>,
			<6088 5616 5264 5079 5038 5029>,
			<6066 5612 5262 5081 5040 5030>,
			<6078 5616 5262 5083 5041 5031>,
			<6103 5625 5263 5085 5043 5033>,
			<6101 5627 5266 5088 5046 5035>,
			<6034 5620 5276 5093 5049 5036>,
			<5964 5610 5283 5099 5052 5038>,
			<5929 5591 5283 5103 5054 5041>,
			<5904 5564 5282 5106 5057 5043>,
			<5898 5547 5278 5111 5061 5047>,
			<5898 5536 5258 5120 5071 5055>,
			<5899 5528 5236 5126 5076 5060>,
			<5886 5519 5221 5111 5065 5052>,
			<5857 5511 5209 5084 5046 5035>,
			<5848 5504 5203 5072 5037 5027>,
			<5855 5498 5199 5068 5032 5024>,
			<5866 5494 5197 5066 5030 5022>,
			<5880 5495 5197 5066 5030 5022>,
			<5900 5500 5199 5068 5031 5022>,
			<5919 5507 5199 5069 5032 5023>,
			<5936 5526 5198 5072 5035 5025>,
			<5953 5550 5198 5074 5038 5029>,
			<5972 5572 5201 5076 5042 5032>,
			<5992 5594 5209 5079 5045 5036>,
			<6012 5618 5217 5081 5046 5038>,
			<6032 5644 5228 5083 5046 5039>,
			<6052 5673 5241 5084 5046 5039>,
			<6075 5703 5253 5084 5043 5036>,
			<6099 5735 5267 5083 5037 5029>,
			<6124 5768 5280 5083 5036 5027>,
			<6148 5800 5293 5083 5039 5032>,
			<6173 5835 5307 5084 5040 5035>,
			<6198 5874 5322 5086 5040 5034>,
			<6224 5919 5339 5088 5039 5031>,
			<6259 5964 5362 5090 5036 5026>,
			<6306 6018 5392 5095 5037 5027>,
			<6357 6073 5406 5100 5050 5044>,
			<6345 6066 5411 5105 5061 5056>,
			<6394 6118 5443 5117 5072 5067>,
			<6451 6174 5477 5129 5081 5074>,
			<6515 6234 5513 5131 5071 5057>,
			<6569 6280 5529 5113 5050 5041>,
			<6653 6331 5566 5117 5052 5043>,
			<6806 6433 5647 5136 5060 5049>,
			<7217 6566 5754 5167 5083 5075>,
			<7217 6566 5754 5167 5083 5075>,
			<7217 6566 5754 5167 5083 5075>;
	};

};

